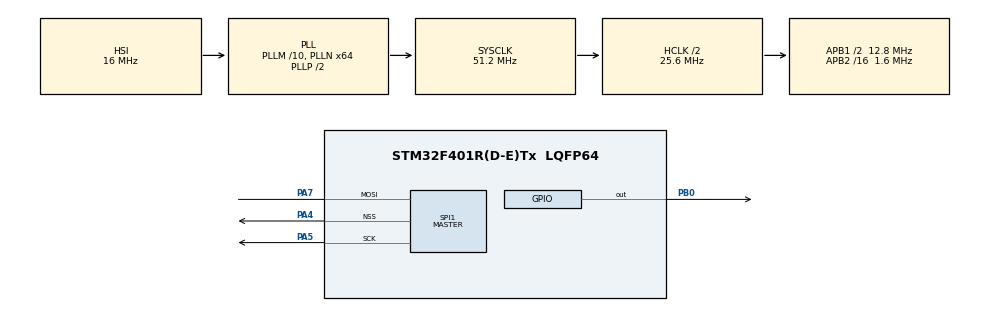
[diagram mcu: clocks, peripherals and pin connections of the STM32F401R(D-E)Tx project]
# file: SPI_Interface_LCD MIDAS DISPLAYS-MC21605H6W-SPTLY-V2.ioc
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Mcu.Family=STM32F4
Mcu.Name=STM32F401R(D-E)Tx
Mcu.Package=LQFP64
NVIC.PriorityGroup=NVIC_PRIORITYGROUP_0
PA4.GPIO_PuPd=GPIO_NOPULL
PA4.Mode=NSS_Signal_Hard_Output
PA4.Signal=SPI1_NSS
PA5.GPIO_PuPd=GPIO_NOPULL
PA5.Mode=Simplex_Bidirectional_Master
PA5.Signal=SPI1_SCK
PA7.GPIO_PuPd=GPIO_NOPULL
PA7.Mode=Simplex_Bidirectional_Master
PA7.Signal=SPI1_MOSI
PB0.PinState=GPIO_PIN_RESET
PB0.Signal=GPIO_Output
ProjectManager.HeapSize=0x200
ProjectManager.StackSize=0x400
ProjectManager.TargetToolchain=STM32CubeIDE
RCC.48MHZClocksFreq_Value=14628571.42857143
RCC.AHBCLKDivider=RCC_SYSCLK_DIV2
RCC.AHBFreq_Value=25600000
RCC.APB1CLKDivider=RCC_HCLK_DIV2
RCC.APB1Freq_Value=12800000
RCC.APB1TimFreq_Value=25600000
RCC.APB2CLKDivider=RCC_HCLK_DIV16
RCC.APB2Freq_Value=1600000
RCC.APB2TimFreq_Value=3200000
RCC.CortexFreq_Value=25600000
RCC.HCLKFreq_Value=25600000
RCC.HSE_VALUE=8000000
RCC.HSI_VALUE=16000000
RCC.LSE_VALUE=32768
RCC.PLLM=10
RCC.PLLN=64
RCC.PLLQ=7
RCC.SYSCLKFreq_VALUE=51200000
RCC.SYSCLKSource=RCC_SYSCLKSOURCE_PLLCLK
RCC.VCOOutputFreq_Value=102400000
SPI1.BaudRatePrescaler=SPI_BAUDRATEPRESCALER_16
SPI1.CLKPhase=SPI_PHASE_1EDGE
SPI1.CLKPolarity=SPI_POLARITY_LOW
SPI1.Direction=SPI_DIRECTION_1LINE
SPI1.FirstBit=SPI_FIRSTBIT_MSB
SPI1.Mode=SPI_MODE_MASTER
SPI1.VirtualNSS=VM_NSSHARD
SPI1.VirtualType=VM_MASTER
board=NUCLEO-F401RE

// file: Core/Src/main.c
/* USER CODE BEGIN Header */
/**
  ******************************************************************************
  * @file           : main.c
  * @brief          : Main program body
  ******************************************************************************
  * @attention
  *
  * Copyright (c) 2024 STMicroelectronics.
  * All rights reserved.
  *
  * This software is licensed under terms that can be found in the LICENSE file
  * in the root directory of this software component.
  * If no LICENSE file comes with this software, it is provided AS-IS.
  *
  ******************************************************************************
  */
/* USER CODE END Header */
#include "main.h"

/* USER CODE BEGIN Includes */
#include <string.h>
#include "MC21605H6W-SPTLY-V2.h"

/* USER CODE END Includes */

/* USER CODE BEGIN PD */
/*
#define ENABLE 0x08
#define DATA_MODE 0x04
#define COMMAND_MODE 0x00

#define LINE_LENGTH 0x40
#define TOT_LENGTH 0x80
*/
/* USER CODE END PD */

void SystemClock_Config(void);
static void MX_GPIO_Init(void);

/*void write_4bit(int nibble, int mode);
void write_cmd(int data) ;
void init_lcd(void);
void write_data(char c);
void set_cursor(int column, int row);
void print_lcd(const char *string) ;*/

int main(void)
{

  /* MCU Configuration--------------------------------------------------------*/

  /* Reset of all peripherals, Initializes the Flash interface and the Systick. */
  HAL_Init();

  /* Configure the system clock */
  SystemClock_Config();

  /* Initialize all configured peripherals */
  MX_GPIO_Init();
  MX_SPI1_Init();
  /* USER CODE BEGIN 2 */

  init_lcd();
  set_cursor(0,0);
  print_lcd("Using LCD");
  set_cursor(0,1);
  print_lcd("On STM32CUBE");
  /* USER CODE END 2 */

  init_lcd();
  set_cursor(3,0);
  print_lcd("Using LCD");
  set_cursor(0,1);
  print_lcd("On STM32CUBE");

  /* Infinite loop */
  while (1)
  {

	/*  set_cursor(2,0);
	  print_lcd("Using LCD");
	  set_cursor(0,1);
	  print_lcd("On STM32CUBE");

	  HAL_Delay(1000);

	  set_cursor(2,0);
	  print_lcd("...........");
	  set_cursor(0,1);
	  print_lcd("...........");

	  HAL_Delay(1000);*/
  }
}

void SystemClock_Config(void)
{
  RCC_OscInitTypeDef RCC_OscInitStruct = {0};
  RCC_ClkInitTypeDef RCC_ClkInitStruct = {0};

  /** Configure the main internal regulator output voltage
  */
  __HAL_RCC_PWR_CLK_ENABLE();
  __HAL_PWR_VOLTAGESCALING_CONFIG(PWR_REGULATOR_VOLTAGE_SCALE2);

  /** Initializes the RCC Oscillators according to the specified parameters
  * in the RCC_OscInitTypeDef structure.
  */
  RCC_OscInitStruct.OscillatorType = RCC_OSCILLATORTYPE_HSI;
  RCC_OscInitStruct.HSIState = RCC_HSI_ON;
  RCC_OscInitStruct.HSICalibrationValue = RCC_HSICALIBRATION_DEFAULT;
  RCC_OscInitStruct.PLL.PLLState = RCC_PLL_ON;
  RCC_OscInitStruct.PLL.PLLSource = RCC_PLLSOURCE_HSI;
  RCC_OscInitStruct.PLL.PLLM = 10;
  RCC_OscInitStruct.PLL.PLLN = 64;
  RCC_OscInitStruct.PLL.PLLP = RCC_PLLP_DIV2;
  RCC_OscInitStruct.PLL.PLLQ = 7;
  if (HAL_RCC_OscConfig(&RCC_OscInitStruct) != HAL_OK)
  {
    Error_Handler();
  }

  /** Initializes the CPU, AHB and APB buses clocks
  */
  RCC_ClkInitStruct.ClockType = RCC_CLOCKTYPE_HCLK|RCC_CLOCKTYPE_SYSCLK
                              |RCC_CLOCKTYPE_PCLK1|RCC_CLOCKTYPE_PCLK2;
  RCC_ClkInitStruct.SYSCLKSource = RCC_SYSCLKSOURCE_PLLCLK;
  RCC_ClkInitStruct.AHBCLKDivider = RCC_SYSCLK_DIV2;
  RCC_ClkInitStruct.APB1CLKDivider = RCC_HCLK_DIV2;
  RCC_ClkInitStruct.APB2CLKDivider = RCC_HCLK_DIV16;

  if (HAL_RCC_ClockConfig(&RCC_ClkInitStruct, FLASH_LATENCY_0) != HAL_OK)
  {
    Error_Handler();
  }
}

static void MX_GPIO_Init(void)
{
  GPIO_InitTypeDef GPIO_InitStruct = {0};

  /* GPIO Ports Clock Enable */
  __HAL_RCC_GPIOA_CLK_ENABLE();
  __HAL_RCC_GPIOB_CLK_ENABLE();

  /*Configure GPIO pin Output Level */
  HAL_GPIO_WritePin(GPIOB, GPIO_PIN_0, GPIO_PIN_RESET);

  /*Configure GPIO pin : PB0 */
  GPIO_InitStruct.Pin = GPIO_PIN_0;
  GPIO_InitStruct.Mode = GPIO_MODE_OUTPUT_PP;
  GPIO_InitStruct.Pull = GPIO_NOPULL;
  GPIO_InitStruct.Speed = GPIO_SPEED_FREQ_LOW;
  HAL_GPIO_Init(GPIOB, &GPIO_InitStruct);

}

void Error_Handler(void)
{
  __disable_irq();
  while (1)
  {
  }
}
